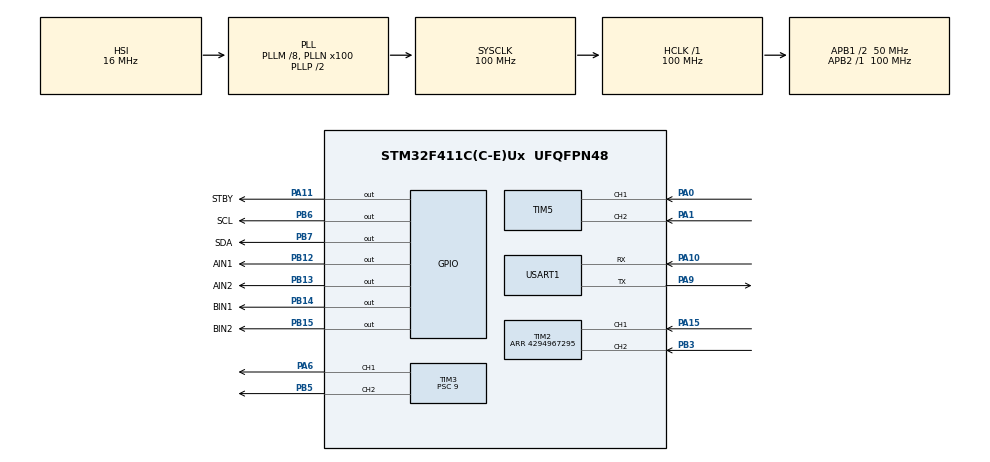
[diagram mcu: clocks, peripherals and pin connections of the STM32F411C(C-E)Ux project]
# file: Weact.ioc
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Dma.Request0=USART1_RX
Dma.Request1=USART1_TX
Dma.USART1_RX.0.Direction=DMA_PERIPH_TO_MEMORY
Dma.USART1_RX.0.FIFOMode=DMA_FIFOMODE_DISABLE
Dma.USART1_RX.0.Instance=DMA2_Stream2
Dma.USART1_RX.0.MemDataAlignment=DMA_MDATAALIGN_BYTE
Dma.USART1_RX.0.MemInc=DMA_MINC_ENABLE
Dma.USART1_RX.0.Mode=DMA_NORMAL
Dma.USART1_RX.0.PeriphDataAlignment=DMA_PDATAALIGN_BYTE
Dma.USART1_RX.0.PeriphInc=DMA_PINC_DISABLE
Dma.USART1_RX.0.Priority=DMA_PRIORITY_LOW
Dma.USART1_TX.1.Direction=DMA_MEMORY_TO_PERIPH
Dma.USART1_TX.1.FIFOMode=DMA_FIFOMODE_DISABLE
Dma.USART1_TX.1.Instance=DMA2_Stream7
Dma.USART1_TX.1.MemDataAlignment=DMA_MDATAALIGN_BYTE
Dma.USART1_TX.1.MemInc=DMA_MINC_ENABLE
Dma.USART1_TX.1.Mode=DMA_NORMAL
Dma.USART1_TX.1.PeriphDataAlignment=DMA_PDATAALIGN_BYTE
Dma.USART1_TX.1.PeriphInc=DMA_PINC_DISABLE
Dma.USART1_TX.1.Priority=DMA_PRIORITY_LOW
Mcu.Family=STM32F4
Mcu.Name=STM32F411C(C-E)Ux
Mcu.Package=UFQFPN48
NVIC.DMA2_Stream2_IRQn=true\:0\:0\:false\:false\:true\:false\:true\:true
NVIC.DMA2_Stream7_IRQn=true\:0\:0\:false\:false\:true\:false\:true\:true
NVIC.PriorityGroup=NVIC_PRIORITYGROUP_4
NVIC.TIM2_IRQn=true\:0\:0\:false\:false\:true\:true\:true\:true
NVIC.TIM3_IRQn=true\:1\:0\:true\:false\:true\:true\:true\:true
NVIC.TIM4_IRQn=true\:1\:0\:true\:false\:true\:true\:true\:true
NVIC.TIM5_IRQn=true\:0\:0\:true\:false\:true\:true\:true\:true
NVIC.USART1_IRQn=true\:2\:0\:true\:false\:true\:true\:true\:true
PA0-WKUP.GPIO_PuPd=GPIO_PULLUP
PA0-WKUP.GPIO_Speed=GPIO_SPEED_FREQ_VERY_HIGH
PA0-WKUP.Signal=S_TIM5_CH1
PA1.GPIO_PuPd=GPIO_PULLUP
PA1.GPIO_Speed=GPIO_SPEED_FREQ_VERY_HIGH
PA1.Signal=S_TIM5_CH2
PA10.Mode=Asynchronous
PA10.Signal=USART1_RX
PA11.GPIO_Label=STBY
PA11.GPIO_PuPd=GPIO_PULLUP
PA11.GPIO_Speed=GPIO_SPEED_FREQ_HIGH
PA11.PinState=GPIO_PIN_SET
PA11.Signal=GPIO_Output
PA15.GPIO_PuPd=GPIO_PULLUP
PA15.GPIO_Speed=GPIO_SPEED_FREQ_VERY_HIGH
PA15.Signal=S_TIM2_CH1_ETR
PA6.GPIO_PuPd=GPIO_PULLUP
PA6.GPIO_Speed=GPIO_SPEED_FREQ_VERY_HIGH
PA6.Signal=S_TIM3_CH1
PA9.Mode=Asynchronous
PA9.Signal=USART1_TX
PB12.GPIO_Label=AIN1
PB12.GPIO_PuPd=GPIO_PULLUP
PB12.GPIO_Speed=GPIO_SPEED_FREQ_HIGH
PB12.Signal=GPIO_Output
PB13.GPIO_Label=AIN2
PB13.GPIO_PuPd=GPIO_PULLUP
PB13.GPIO_Speed=GPIO_SPEED_FREQ_HIGH
PB13.Signal=GPIO_Output
PB14.GPIO_Label=BIN1
PB14.GPIO_PuPd=GPIO_PULLUP
PB14.GPIO_Speed=GPIO_SPEED_FREQ_HIGH
PB14.Signal=GPIO_Output
PB15.GPIO_Label=BIN2
PB15.GPIO_PuPd=GPIO_PULLUP
PB15.GPIO_Speed=GPIO_SPEED_FREQ_HIGH
PB15.Signal=GPIO_Output
PB3.GPIO_PuPd=GPIO_PULLUP
PB3.GPIO_Speed=GPIO_SPEED_FREQ_VERY_HIGH
PB3.Signal=S_TIM2_CH2
PB5.GPIO_PuPd=GPIO_PULLUP
PB5.GPIO_Speed=GPIO_SPEED_FREQ_VERY_HIGH
PB5.Signal=S_TIM3_CH2
PB6.GPIO_Label=SCL
PB6.GPIO_PuPd=GPIO_PULLUP
PB6.GPIO_Speed=GPIO_SPEED_FREQ_HIGH
PB6.PinState=GPIO_PIN_SET
PB6.Signal=GPIO_Output
PB7.GPIO_Label=SDA
PB7.GPIO_PuPd=GPIO_PULLUP
PB7.GPIO_Speed=GPIO_SPEED_FREQ_HIGH
PB7.PinState=GPIO_PIN_SET
PB7.Signal=GPIO_Output
PH0\ -\ OSC_IN.Mode=HSE-External-Oscillator
PH0\ -\ OSC_IN.Signal=RCC_OSC_IN
PH1\ -\ OSC_OUT.Mode=HSE-External-Oscillator
PH1\ -\ OSC_OUT.Signal=RCC_OSC_OUT
ProjectManager.HeapSize=0x200
ProjectManager.StackSize=0x400
ProjectManager.TargetToolchain=MDK-ARM V5.32
RCC.48MHZClocksFreq_Value=50000000
RCC.AHBFreq_Value=100000000
RCC.APB1CLKDivider=RCC_HCLK_DIV2
RCC.APB1Freq_Value=50000000
RCC.APB1TimFreq_Value=100000000
RCC.APB2Freq_Value=100000000
RCC.APB2TimFreq_Value=100000000
RCC.CortexFreq_Value=100000000
RCC.HCLKFreq_Value=100000000
RCC.HSE_VALUE=25000000
RCC.HSI_VALUE=16000000
RCC.LSE_VALUE=32768
RCC.PLLM=8
RCC.PLLN=100
RCC.SYSCLKFreq_VALUE=100000000
RCC.SYSCLKSource=RCC_SYSCLKSOURCE_PLLCLK
RCC.VCOOutputFreq_Value=200000000
SH.S_TIM2_CH1_ETR.0=TIM2_CH1,Encoder_Interface
SH.S_TIM2_CH2.0=TIM2_CH2,Encoder_Interface
SH.S_TIM3_CH1.0=TIM3_CH1,PWM Generation1 CH1
SH.S_TIM3_CH2.0=TIM3_CH2,PWM Generation2 CH2
SH.S_TIM5_CH1.0=TIM5_CH1,Encoder_Interface
SH.S_TIM5_CH2.0=TIM5_CH2,Encoder_Interface
TIM2.Period=4294967295
TIM3.Channel-PWM\ Generation1\ CH1=TIM_CHANNEL_1
TIM3.Channel-PWM\ Generation2\ CH2=TIM_CHANNEL_2
TIM3.Period=1000
TIM3.Prescaler=9
TIM4.Period=99
TIM4.Prescaler=9999
USART1.VirtualMode=VM_ASYNC
VP_TIM4_VS_ClockSourceINT.Mode=Internal
board=custom

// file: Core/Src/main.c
/* USER CODE BEGIN Header */
/**
  ******************************************************************************
  * @file           : main.c
  * @brief          : Main program body
  ******************************************************************************
  * @attention
  *
  * Copyright (c) 2023 STMicroelectronics.
  * All rights reserved.
  *
  * This software is licensed under terms that can be found in the LICENSE file
  * in the root directory of this software component.
  * If no LICENSE file comes with this software, it is provided AS-IS.
  *
  ******************************************************************************
  */
/* USER CODE END Header */
#include "main.h"
#include "dma.h"
#include "tim.h"
#include "usart.h"
#include "gpio.h"

/* USER CODE BEGIN Includes */
#include "TB6612.h"
#include "pid.h"
#include "oled.h"
#include "stdio.h"

/* USER CODE END Includes */

void SystemClock_Config(void);

int main(void)
{

  /* MCU Configuration--------------------------------------------------------*/

  /* Reset of all peripherals, Initializes the Flash interface and the Systick. */
  HAL_Init();

  /* Configure the system clock */
  SystemClock_Config();

  /* Initialize all configured peripherals */
  MX_GPIO_Init();
  MX_DMA_Init();
  MX_TIM2_Init();
  MX_TIM3_Init();
  MX_TIM4_Init();
  MX_TIM5_Init();
  MX_USART1_UART_Init();
  /* USER CODE BEGIN 2 */
	Motor_Init();
	OLED_Init();
	OLED_Display_Buffer(0,0,"Okk");
	PID2_Init(&PidASpeed,SpeedA_KP1,SpeedA_KI1,SpeedA_KD1);
	PID1_Init(&PidALocation,LocationA_KP1,LocationA_KI1,LocationA_KD1,100,100);

	PID2_Init(&PidBSpeed,SpeedB_KP1,SpeedB_KI1,SpeedB_KD1);
	PID1_Init(&PidBLocation,LocationB_KP1,LocationB_KI1,LocationB_KD1,100,100);
	MOtor_SetState(1);
	EncoderA.SpeedIn=0.0f;
	EncoderB.SpeedIn=0.1f;

  /* USER CODE END 2 */

  /* Infinite loop */
  while (1)
  {

  }
}

void SystemClock_Config(void)
{
  RCC_OscInitTypeDef RCC_OscInitStruct = {0};
  RCC_ClkInitTypeDef RCC_ClkInitStruct = {0};

  /** Configure the main internal regulator output voltage
  */
  __HAL_RCC_PWR_CLK_ENABLE();
  __HAL_PWR_VOLTAGESCALING_CONFIG(PWR_REGULATOR_VOLTAGE_SCALE1);

  /** Initializes the RCC Oscillators according to the specified parameters
  * in the RCC_OscInitTypeDef structure.
  */
  RCC_OscInitStruct.OscillatorType = RCC_OSCILLATORTYPE_HSI;
  RCC_OscInitStruct.HSIState = RCC_HSI_ON;
  RCC_OscInitStruct.HSICalibrationValue = RCC_HSICALIBRATION_DEFAULT;
  RCC_OscInitStruct.PLL.PLLState = RCC_PLL_ON;
  RCC_OscInitStruct.PLL.PLLSource = RCC_PLLSOURCE_HSI;
  RCC_OscInitStruct.PLL.PLLM = 8;
  RCC_OscInitStruct.PLL.PLLN = 100;
  RCC_OscInitStruct.PLL.PLLP = RCC_PLLP_DIV2;
  RCC_OscInitStruct.PLL.PLLQ = 4;
  if (HAL_RCC_OscConfig(&RCC_OscInitStruct) != HAL_OK)
  {
    Error_Handler();
  }

  /** Initializes the CPU, AHB and APB buses clocks
  */
  RCC_ClkInitStruct.ClockType = RCC_CLOCKTYPE_HCLK|RCC_CLOCKTYPE_SYSCLK
                              |RCC_CLOCKTYPE_PCLK1|RCC_CLOCKTYPE_PCLK2;
  RCC_ClkInitStruct.SYSCLKSource = RCC_SYSCLKSOURCE_PLLCLK;
  RCC_ClkInitStruct.AHBCLKDivider = RCC_SYSCLK_DIV1;
  RCC_ClkInitStruct.APB1CLKDivider = RCC_HCLK_DIV2;
  RCC_ClkInitStruct.APB2CLKDivider = RCC_HCLK_DIV1;

  if (HAL_RCC_ClockConfig(&RCC_ClkInitStruct, FLASH_LATENCY_3) != HAL_OK)
  {
    Error_Handler();
  }
}

void Error_Handler(void)
{
  __disable_irq();
  while (1)
  {
  }
}
